AUTOSAR XML (schema 00046)
package /ComponentTypes
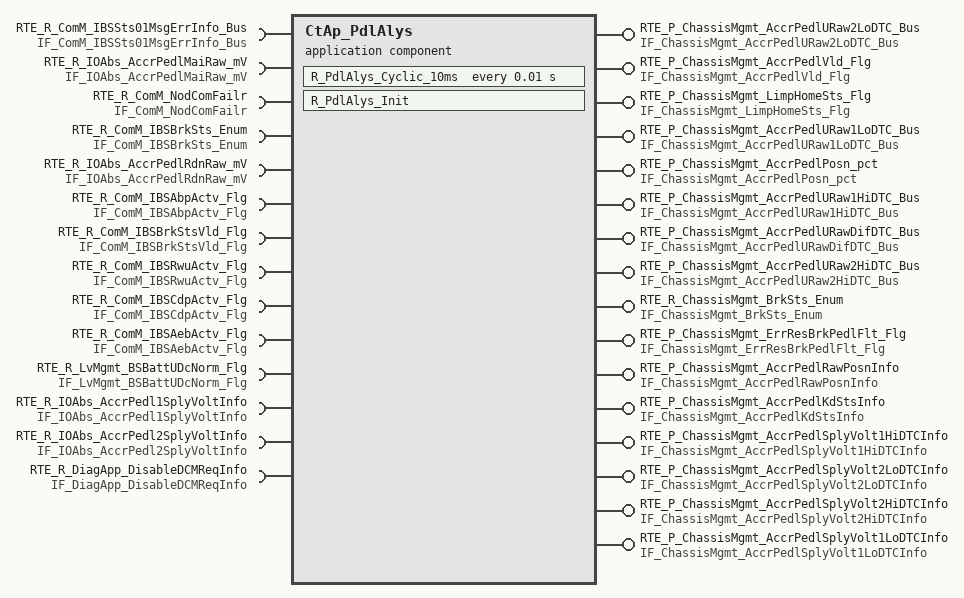
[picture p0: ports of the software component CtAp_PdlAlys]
  application sw component type CtAp_PdlAlys
    5 x require port:
      RTE_R_ComM_IBSSts01MsgErrInfo_Bus: required-interface=IF_ComM_IBSSts01MsgErrInfo_Bus
        required-com-specs:
          data-element=tec_ComM_IBSSts01CRCDTCInfo_Bus, filter=data-filter-type=ALWAYS, init-value=fields=[ComM_MonStatIBSSts01CRCDTCErrorInfo:0, ComM_MonResIBSSts01CRCDTCErrorInfo:0, ComM_ErrStatIBSSts01CRCDTCErrorInfo:0, ComM_ErrResIBSSts01CRCDTCErrorInfo:0]
          data-element=tec_ComM_IBSSts01TimeoutDTCInfo_Bus, filter=data-filter-type=ALWAYS, init-value=fields=[ComM_MonStatIBSSts01TimeoutDTCErrorInfo:0, ComM_MonResIBSSts01TimeoutDTCErrorInfo:0, ComM_ErrStatIBSSts01TimeoutDTCErrorInfo:0, ComM_ErrResIBSSts01TimeoutDTCErrorInfo:0]
          data-element=tec_ComM_IBSSts01CRCInfo_Bus, filter=data-filter-type=ALWAYS, init-value=fields=[ComM_MonStatIBSSts01CRCErrorInfo:0, ComM_MonResIBSSts01CRCErrorInfo:0, ComM_ErrStatIBSSts01CRCErrorInfo:0, ComM_ErrResIBSSts01CRCErrorInfo:0]
          data-element=tec_ComM_IBSSts01E2ETimeoutInfo_Bus, filter=data-filter-type=ALWAYS, init-value=fields=[ComM_MonStatIBSSts01E2ETimeoutInfo:0, ComM_MonResIBSSts01E2ETimeoutInfo:0, ComM_ErrStatIBSSts01E2ETimeoutInfo:0, ComM_ErrResIBSSts01E2ETimeoutInfo:0]
      RTE_R_IOAbs_AccrPedlMaiRaw_mV: nonqueued-receiver-com-spec{data-element=tec_IOAbs_AccrPedlMaiRaw_mV, filter=data-filter-type=ALWAYS, init-value=0}, required-interface=IF_IOAbs_AccrPedlMaiRaw_mV
      RTE_R_ComM_NodComFailr: required-interface=IF_ComM_NodComFailr
        required-com-specs:
          data-element=tec_ComM_SGWNodComFailr_Flg, filter=data-filter-type=ALWAYS, init-value=0
          data-element=tec_ComM_CGWNodComFailr_Flg, filter=data-filter-type=ALWAYS, init-value=0
          data-element=tec_ComM_TCUNodComFailr_Flg, filter=data-filter-type=ALWAYS, init-value=0
          data-element=tec_ComM_BCMNodComFailr_Flg, filter=data-filter-type=ALWAYS, init-value=0
          data-element=tec_ComM_PRNDNodComFailr_Flg, filter=data-filter-type=ALWAYS, init-value=0
          data-element=tec_ComM_IVINodComFailr_Flg, filter=data-filter-type=ALWAYS, init-value=0
          data-element=tec_ComM_DCDCNodComFailr_Flg, filter=data-filter-type=ALWAYS, init-value=0
          data-element=tec_ComM_OBCNodComFailr_Flg, filter=data-filter-type=ALWAYS, init-value=0
          data-element=tec_ComM_CHIBSNodComFailr_Flg, filter=data-filter-type=ALWAYS, init-value=0
          data-element=tec_ComM_MCUNodComFailr_Flg, filter=data-filter-type=ALWAYS, init-value=0
          data-element=tec_ComM_EVCOMNodComFailr_Flg, filter=data-filter-type=ALWAYS, init-value=0
          data-element=tec_ComM_EPTIBSNodComFailr_Flg, filter=data-filter-type=ALWAYS, init-value=0
          data-element=tec_ComM_DCMNodComFailr_Flg, filter=data-filter-type=ALWAYS, init-value=0
          data-element=tec_ComM_BMSNodComFailr_Flg, filter=data-filter-type=ALWAYS, init-value=0
          data-element=tec_ComM_ACUNodComFailr_Flg, filter=data-filter-type=ALWAYS, init-value=0
          data-element=tec_ComM_APTCNodComFailr_Flg, filter=data-filter-type=ALWAYS, init-value=0
          data-element=tec_ComM_ADCUNodComFailr_Flg, filter=data-filter-type=ALWAYS, init-value=0
          data-element=tec_ComM_DCMRRNodComFailr_Flg, filter=data-filter-type=ALWAYS, init-value=0
          data-element=tec_ComM_DCMRLNodComFailr_Flg, filter=data-filter-type=ALWAYS, init-value=0
          data-element=tec_ComM_DCMFRNodComFailr_Flg, filter=data-filter-type=ALWAYS, init-value=0
          data-element=tec_ComM_DCMFLNodComFailr_Flg, filter=data-filter-type=ALWAYS, init-value=0
          data-element=tec_ComM_SGWCHNodComFailr_Flg, init-value=0
      RTE_R_ComM_IBSBrkSts_Enum: nonqueued-receiver-com-spec{data-element=tec_ComM_IBSBrkSts_Enum, filter=data-filter-type=ALWAYS, init-value=0}, required-interface=IF_ComM_IBSBrkSts_Enum
      RTE_R_IOAbs_AccrPedlRdnRaw_mV: nonqueued-receiver-com-spec{data-element=tec_IOAbs_AccrPedlRdnRaw_mV, filter=data-filter-type=ALWAYS, init-value=0}, required-interface=IF_IOAbs_AccrPedlRdnRaw_mV
    8 x provide port:
      RTE_P_ChassisMgmt_AccrPedlURaw2LoDTC_Bus: nonqueued-sender-com-spec{data-element=tec_ChassisMgmt_AccrPedlURaw2LoDTC_Bus, init-value=fields=[ChassisMgmt_MonStatAccrPedlURaw2Lo:0, ChassisMgmt_MonResAccrPedlURaw2Lo:0, ChassisMgmt_ErrStatAccrPedlURaw2Lo:0, ChassisMgmt_ErrResAccrPedlURaw2Lo:0]}, provided-interface=IF_ChassisMgmt_AccrPedlURaw2LoDTC_Bus
      RTE_P_ChassisMgmt_AccrPedlVld_Flg: nonqueued-sender-com-spec{data-element=tec_ChassisMgmt_AccrPedlVld_Flg, init-value=0}, provided-interface=IF_ChassisMgmt_AccrPedlVld_Flg
      RTE_P_ChassisMgmt_LimpHomeSts_Flg: nonqueued-sender-com-spec{data-element=tec_ChassisMgmt_LimpHomeSts_Flg, init-value=0}, provided-interface=IF_ChassisMgmt_LimpHomeSts_Flg
      RTE_P_ChassisMgmt_AccrPedlURaw1LoDTC_Bus: nonqueued-sender-com-spec{data-element=tec_ChassisMgmt_AccrPedlURaw1LoDTC_Bus, init-value=fields=[ChassisMgmt_MonStatAccrPedlURaw1Lo:0, ChassisMgmt_MonResAccrPedlURaw1Lo:0, ChassisMgmt_ErrStatAccrPedlURaw1Lo:0, ChassisMgmt_ErrResAccrPedlURaw1Lo:0]}, provided-interface=IF_ChassisMgmt_AccrPedlURaw1LoDTC_Bus
      RTE_P_ChassisMgmt_AccrPedlPosn_pct: nonqueued-sender-com-spec{data-element=tec_ChassisMgmt_AccrPedlPosn_pct, init-value=0}, provided-interface=IF_ChassisMgmt_AccrPedlPosn_pct
      RTE_P_ChassisMgmt_AccrPedlURaw1HiDTC_Bus: nonqueued-sender-com-spec{data-element=tec_ChassisMgmt_AccrPedlURaw1HiDTC_Bus, init-value=fields=[ChassisMgmt_MonStatAccrPedlURaw1Hi:0, ChassisMgmt_MonResAccrPedlURaw1Hi:0, ChassisMgmt_ErrStatAccrPedlURaw1Hi:0, ChassisMgmt_ErrResAccrPedlURaw1Hi:0]}, provided-interface=IF_ChassisMgmt_AccrPedlURaw1HiDTC_Bus
      RTE_P_ChassisMgmt_AccrPedlURawDifDTC_Bus: nonqueued-sender-com-spec{data-element=tec_ChassisMgmt_AccrPedlURawDifDTC_Bus, init-value=fields=[ChassisMgmt_MonStatAccrPedlURawDif:0, ChassisMgmt_MonResAccrPedlURawDif:0, ChassisMgmt_ErrStatAccrPedlURawDif:0, ChassisMgmt_ErrResAccrPedlURawDif:0]}, provided-interface=IF_ChassisMgmt_AccrPedlURawDifDTC_Bus
      RTE_P_ChassisMgmt_AccrPedlURaw2HiDTC_Bus: nonqueued-sender-com-spec{data-element=tec_ChassisMgmt_AccrPedlURaw2HiDTC_Bus, init-value=fields=[ChassisMgmt_MonStatAccrPedlURaw2Hi:0, ChassisMgmt_MonResAccrPedlURaw2Hi:0, ChassisMgmt_ErrStatAccrPedlURaw2Hi:0, ChassisMgmt_ErrResAccrPedlURaw2Hi:0]}, provided-interface=IF_ChassisMgmt_AccrPedlURaw2HiDTC_Bus
    6 x require port:
      RTE_R_ComM_IBSAbpActv_Flg: nonqueued-receiver-com-spec{data-element=tec_ComM_IBSAbpActv_Flg, filter=data-filter-type=ALWAYS, init-value=0}, required-interface=IF_ComM_IBSAbpActv_Flg
      RTE_R_ComM_IBSBrkStsVld_Flg: nonqueued-receiver-com-spec{data-element=tec_ComM_IBSBrkStsVld_Flg, filter=data-filter-type=ALWAYS, init-value=0}, required-interface=IF_ComM_IBSBrkStsVld_Flg
      RTE_R_ComM_IBSRwuActv_Flg: nonqueued-receiver-com-spec{data-element=tec_ComM_IBSRwuActv_Flg, filter=data-filter-type=ALWAYS, init-value=0}, required-interface=IF_ComM_IBSRwuActv_Flg
      RTE_R_ComM_IBSCdpActv_Flg: nonqueued-receiver-com-spec{data-element=tec_ComM_IBSCdpActv_Flg, filter=data-filter-type=ALWAYS, init-value=0}, required-interface=IF_ComM_IBSCdpActv_Flg
      RTE_R_ComM_IBSAebActv_Flg: nonqueued-receiver-com-spec{data-element=tec_ComM_IBSAebActv_Flg, filter=data-filter-type=ALWAYS, init-value=0}, required-interface=IF_ComM_IBSAebActv_Flg
      RTE_R_LvMgmt_BSBattUDcNorm_Flg: nonqueued-receiver-com-spec{data-element=tec_LvMgmt_BSBattUDcNorm_Flg, filter=data-filter-type=ALWAYS, init-value=0}, required-interface=IF_LvMgmt_BSBattUDcNorm_Flg
    provide port RTE_R_ChassisMgmt_BrkSts_Enum: nonqueued-sender-com-spec{data-element=tec_ChassisMgmt_BrkSts_Enum, init-value=0}, provided-interface=IF_ChassisMgmt_BrkSts_Enum
    provide port RTE_P_ChassisMgmt_ErrResBrkPedlFlt_Flg: nonqueued-sender-com-spec{data-element=tec_ChassisMgmt_ErrResBrkPedlFlt_Flg, init-value=0}, provided-interface=IF_ChassisMgmt_ErrResBrkPedlFlt_Flg
    require port RTE_R_IOAbs_AccrPedl1SplyVoltInfo: nonqueued-receiver-com-spec{data-element=tec_IOAbs_AccrPedl1SplyVoltInfo, filter=data-filter-type=ALWAYS, init-value=0}, required-interface=IF_IOAbs_AccrPedl1SplyVoltInfo
    require port RTE_R_IOAbs_AccrPedl2SplyVoltInfo: nonqueued-receiver-com-spec{data-element=tec_IOAbs_AccrPedl2SplyVoltInfo, filter=data-filter-type=ALWAYS, init-value=0}, required-interface=IF_IOAbs_AccrPedl2SplyVoltInfo
    6 x provide port:
      RTE_P_ChassisMgmt_AccrPedlRawPosnInfo: nonqueued-sender-com-spec{data-element=tec_ChassisMgmt_AccrPedlRawPosnInfo, init-value=0}, provided-interface=IF_ChassisMgmt_AccrPedlRawPosnInfo
      RTE_P_ChassisMgmt_AccrPedlKdStsInfo: nonqueued-sender-com-spec{data-element=tec_ChassisMgmt_AccrPedlKdStsInfo, init-value=0}, provided-interface=IF_ChassisMgmt_AccrPedlKdStsInfo
      RTE_P_ChassisMgmt_AccrPedlSplyVolt1HiDTCInfo: nonqueued-sender-com-spec{data-element=tec_ChassisMgmt_AccrPedlSplyVolt1HiDTCInfo, init-value=fields=[ChassisMgmt_MonStatAccrPedlSplyVolt1HiInfo:0, ChassisMgmt_MonResAccrPedlSplyVolt1HiInfo:0, ChassisMgmt_ErrStatAccrPedlSplyVolt1HiInfo:0, ChassisMgmt_ErrResAccrPedlSplyVolt1HiInfo:0]}, provided-interface=IF_ChassisMgmt_AccrPedlSplyVolt1HiDTCInfo
      RTE_P_ChassisMgmt_AccrPedlSplyVolt2LoDTCInfo: nonqueued-sender-com-spec{data-element=tec_ChassisMgmt_AccrPedlSplyVolt2LoDTCInfo, init-value=fields=[ChassisMgmt_MonStatAccrPedlSplyVolt2LoInfo:0, ChassisMgmt_MonResAccrPedlSplyVolt2LoInfo:0, ChassisMgmt_ErrStatAccrPedlSplyVolt2LoInfo:0, ChassisMgmt_ErrResAccrPedlSplyVolt2LoInfo:0]}, provided-interface=IF_ChassisMgmt_AccrPedlSplyVolt2LoDTCInfo
      RTE_P_ChassisMgmt_AccrPedlSplyVolt2HiDTCInfo: nonqueued-sender-com-spec{data-element=tec_ChassisMgmt_AccrPedlSplyVolt2HiDTCInfo, init-value=fields=[ChassisMgmt_MonStatAccrPedlSplyVolt2HiInfo:0, ChassisMgmt_MonResAccrPedlSplyVolt2HiInfo:0, ChassisMgmt_ErrStatAccrPedlSplyVolt2HiInfo:0, ChassisMgmt_ErrResAccrPedlSplyVolt2HiInfo:0]}, provided-interface=IF_ChassisMgmt_AccrPedlSplyVolt2HiDTCInfo
      RTE_P_ChassisMgmt_AccrPedlSplyVolt1LoDTCInfo: nonqueued-sender-com-spec{data-element=tec_ChassisMgmt_AccrPedlSplyVolt1LoDTCInfo, init-value=fields=[ChassisMgmt_MonStatAccrPedlSplyVolt1LoInfo:0, ChassisMgmt_MonResAccrPedlSplyVolt1LoInfo:0, ChassisMgmt_ErrStatAccrPedlSplyVolt1LoInfo:0, ChassisMgmt_ErrResAccrPedlSplyVolt1LoInfo:0]}, provided-interface=IF_ChassisMgmt_AccrPedlSplyVolt1LoDTCInfo
    require port RTE_R_DiagApp_DisableDCMReqInfo: nonqueued-receiver-com-spec{data-element=tec_DiagApp_DisableDCMReqInfo, filter=data-filter-type=ALWAYS, init-value=0}, required-interface=IF_DiagApp_DisableDCMReqInfo
    behavior CtAp_PdlAlys_InternalBehavior
      timing event TMT_R_PdlAlys_Cyclic_10ms: start-on-event=R_PdlAlys_Cyclic_10ms, period=0.01
      init event CtAp_PdlAlys_InitEvent: start-on-event=R_PdlAlys_Init
      runnable R_PdlAlys_Cyclic_10ms
        data-receive-point-by-arguments:
          15 x access:
            REC_RTE_R_ComM_IBSAbpActv_Flg_tec_ComM_IBSAbpActv_Flg: accessed-variable=RTE_R_ComM_IBSAbpActv_Flg.tec_ComM_IBSAbpActv_Flg
            REC_RTE_R_ComM_IBSAebActv_Flg_tec_ComM_IBSAebActv_Flg: accessed-variable=RTE_R_ComM_IBSAebActv_Flg.tec_ComM_IBSAebActv_Flg
            REC_RTE_R_ComM_IBSBrkStsVld_Flg_tec_ComM_IBSBrkStsVld_Flg: accessed-variable=RTE_R_ComM_IBSBrkStsVld_Flg.tec_ComM_IBSBrkStsVld_Flg
            REC_RTE_R_ComM_IBSBrkSts_Enum_tec_ComM_IBSBrkSts_Enum: accessed-variable=RTE_R_ComM_IBSBrkSts_Enum.tec_ComM_IBSBrkSts_Enum
            REC_RTE_R_ComM_IBSCdpActv_Flg_tec_ComM_IBSCdpActv_Flg: accessed-variable=RTE_R_ComM_IBSCdpActv_Flg.tec_ComM_IBSCdpActv_Flg
            REC_RTE_R_ComM_IBSRwuActv_Flg_tec_ComM_IBSRwuActv_Flg: accessed-variable=RTE_R_ComM_IBSRwuActv_Flg.tec_ComM_IBSRwuActv_Flg
            REC_RTE_R_ComM_IBSSts01MsgErrInfo_Bus_tec_ComM_IBSSts01CRCInfo_Bus: accessed-variable=RTE_R_ComM_IBSSts01MsgErrInfo_Bus.tec_ComM_IBSSts01CRCInfo_Bus
            REC_RTE_R_ComM_NodComFailr_tec_ComM_CHIBSNodComFailr_Flg: accessed-variable=RTE_R_ComM_NodComFailr.tec_ComM_CHIBSNodComFailr_Flg
            REC_RTE_R_IOAbs_AccrPedlMaiRaw_mV_tec_IOAbs_AccrPedlMaiRaw_mV: accessed-variable=RTE_R_IOAbs_AccrPedlMaiRaw_mV.tec_IOAbs_AccrPedlMaiRaw_mV
            REC_RTE_R_IOAbs_AccrPedlRdnRaw_mV_tec_IOAbs_AccrPedlRdnRaw_mV: accessed-variable=RTE_R_IOAbs_AccrPedlRdnRaw_mV.tec_IOAbs_AccrPedlRdnRaw_mV
            REC_RTE_R_LvMgmt_BSBattUDcNorm_Flg_tec_LvMgmt_BSBattUDcNorm_Flg: accessed-variable=RTE_R_LvMgmt_BSBattUDcNorm_Flg.tec_LvMgmt_BSBattUDcNorm_Flg
            REC_RTE_R_DiagApp_DisableDCMReqInfo_tec_DiagApp_DisableDCMReqInfo: accessed-variable=RTE_R_DiagApp_DisableDCMReqInfo.tec_DiagApp_DisableDCMReqInfo
            REC_RTE_R_IOAbs_AccrPedl1SplyVoltInfo_tec_IOAbs_AccrPedl1SplyVoltInfo: accessed-variable=RTE_R_IOAbs_AccrPedl1SplyVoltInfo.tec_IOAbs_AccrPedl1SplyVoltInfo
            REC_RTE_R_IOAbs_AccrPedl2SplyVoltInfo_tec_IOAbs_AccrPedl2SplyVoltInfo: accessed-variable=RTE_R_IOAbs_AccrPedl2SplyVoltInfo.tec_IOAbs_AccrPedl2SplyVoltInfo
            REC_RTE_R_ComM_IBSSts01MsgErrInfo_Bus_tec_ComM_IBSSts01E2ETimeoutInfo_Bus: accessed-variable=RTE_R_ComM_IBSSts01MsgErrInfo_Bus.tec_ComM_IBSSts01E2ETimeoutInfo_Bus
        data-send-points:
          16 x access:
            SEND_RTE_P_ChassisMgmt_AccrPedlPosn_pct_tec_ChassisMgmt_AccrPedlPosn_pct: accessed-variable=RTE_P_ChassisMgmt_AccrPedlPosn_pct.tec_ChassisMgmt_AccrPedlPosn_pct
            SEND_RTE_P_ChassisMgmt_AccrPedlURaw1HiDTC_Bus_tec_ChassisMgmt_AccrPedlURaw1HiDTC_Bus: accessed-variable=RTE_P_ChassisMgmt_AccrPedlURaw1HiDTC_Bus.tec_ChassisMgmt_AccrPedlURaw1HiDTC_Bus
            SEND_RTE_P_ChassisMgmt_AccrPedlURaw1LoDTC_Bus_tec_ChassisMgmt_AccrPedlURaw1LoDTC_Bus: accessed-variable=RTE_P_ChassisMgmt_AccrPedlURaw1LoDTC_Bus.tec_ChassisMgmt_AccrPedlURaw1LoDTC_Bus
            SEND_RTE_P_ChassisMgmt_AccrPedlURaw2HiDTC_Bus_tec_ChassisMgmt_AccrPedlURaw2HiDTC_Bus: accessed-variable=RTE_P_ChassisMgmt_AccrPedlURaw2HiDTC_Bus.tec_ChassisMgmt_AccrPedlURaw2HiDTC_Bus
            SEND_RTE_P_ChassisMgmt_AccrPedlURaw2LoDTC_Bus_tec_ChassisMgmt_AccrPedlURaw2LoDTC_Bus: accessed-variable=RTE_P_ChassisMgmt_AccrPedlURaw2LoDTC_Bus.tec_ChassisMgmt_AccrPedlURaw2LoDTC_Bus
            SEND_RTE_P_ChassisMgmt_AccrPedlURawDifDTC_Bus_tec_ChassisMgmt_AccrPedlURawDifDTC_Bus: accessed-variable=RTE_P_ChassisMgmt_AccrPedlURawDifDTC_Bus.tec_ChassisMgmt_AccrPedlURawDifDTC_Bus
            SEND_RTE_P_ChassisMgmt_AccrPedlVld_Flg_tec_ChassisMgmt_AccrPedlVld_Flg: accessed-variable=RTE_P_ChassisMgmt_AccrPedlVld_Flg.tec_ChassisMgmt_AccrPedlVld_Flg
            SEND_RTE_P_ChassisMgmt_LimpHome_Flg_tec_ChassisMgmt_LimpHome_Flg: accessed-variable=RTE_P_ChassisMgmt_LimpHomeSts_Flg.tec_ChassisMgmt_LimpHomeSts_Flg
            SEND_RTE_R_ChassisMgmt_BrkSts_Enum_tec_ChassisMgmt_BrkSts_Enum: accessed-variable=RTE_R_ChassisMgmt_BrkSts_Enum.tec_ChassisMgmt_BrkSts_Enum
            SEND_RTE_P_ChassisMgmt_ErrResBrkPedlFlt_Flg_tec_ChassisMgmt_ErrResBrkPedlFlt_Flg: accessed-variable=RTE_P_ChassisMgmt_ErrResBrkPedlFlt_Flg.tec_ChassisMgmt_ErrResBrkPedlFlt_Flg
            SEND_RTE_P_ChassisMgmt_AccrPedlKdStsInfo_tec_ChassisMgmt_AccrPedlKdStsInfo: accessed-variable=RTE_P_ChassisMgmt_AccrPedlKdStsInfo.tec_ChassisMgmt_AccrPedlKdStsInfo
            SEND_RTE_P_ChassisMgmt_AccrPedlRawPosnInfo_tec_ChassisMgmt_AccrPedlRawPosnInfo: accessed-variable=RTE_P_ChassisMgmt_AccrPedlRawPosnInfo.tec_ChassisMgmt_AccrPedlRawPosnInfo
            SEND_RTE_P_ChassisMgmt_AccrPedlSplyVolt1HiDTCInfo_tec_ChassisMgmt_AccrPedlSplyVolt1HiDTCInfo: accessed-variable=RTE_P_ChassisMgmt_AccrPedlSplyVolt1HiDTCInfo.tec_ChassisMgmt_AccrPedlSplyVolt1HiDTCInfo
            SEND_RTE_P_ChassisMgmt_AccrPedlSplyVolt1LoDTCInfo_tec_ChassisMgmt_AccrPedlSplyVolt1LoDTCInfo: accessed-variable=RTE_P_ChassisMgmt_AccrPedlSplyVolt1LoDTCInfo.tec_ChassisMgmt_AccrPedlSplyVolt1LoDTCInfo
            SEND_RTE_P_ChassisMgmt_AccrPedlSplyVolt2HiDTCInfo_tec_ChassisMgmt_AccrPedlSplyVolt2HiDTCInfo: accessed-variable=RTE_P_ChassisMgmt_AccrPedlSplyVolt2HiDTCInfo.tec_ChassisMgmt_AccrPedlSplyVolt2HiDTCInfo
            SEND_RTE_P_ChassisMgmt_AccrPedlSplyVolt2LoDTCInfo_tec_ChassisMgmt_AccrPedlSplyVolt2LoDTCInfo: accessed-variable=RTE_P_ChassisMgmt_AccrPedlSplyVolt2LoDTCInfo.tec_ChassisMgmt_AccrPedlSplyVolt2LoDTCInfo
      runnable R_PdlAlys_Init
  swc implementation CtAp_PdlAlys_Implementation: behavior=CtAp_PdlAlys_InternalBehavior
